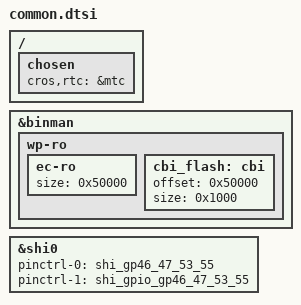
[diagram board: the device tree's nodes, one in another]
/* Copyright 2025 The ChromiumOS Authors
 * Use of this source code is governed by a BSD-style license that can be
 * found in the LICENSE file.
 */

#include <cros/cbi_flash.dtsi>

&binman {
	wp-ro {
		ec-ro {
			size = <0x50000>;
		};
		cbi_flash: cbi {
			/*
			 * CBI section size is 0x1000 bytes, the
			 * CBI portion lies at the end of EC_RO section.
			 * EC_RO section ends at 0x50000 byte which
			 * is the offset.
			 */
			offset = <0x50000>;
			size = <0x1000>;
		};
	};
};

/* AP interface */
&shi0 {
	status = "okay";
	pinctrl-0 = <&shi_gp46_47_53_55>;
	pinctrl-1 = <&shi_gpio_gp46_47_53_55>;
	pinctrl-names = "default", "sleep";
};

/ {
chosen {
		cros,rtc = &mtc;
	};
};
